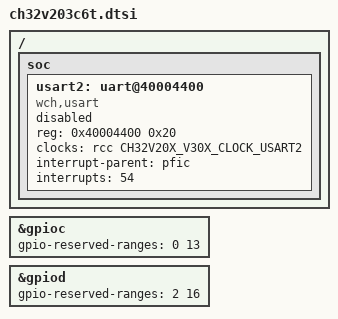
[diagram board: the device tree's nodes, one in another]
/*
 * Copyright (c) 2025 MASSDRIVER EI (massdriver.space)
 *
 * SPDX-License-Identifier: Apache-2.0
 */

#include <wch/ch32v203/ch32v203.dtsi>

/ {
	soc {
		usart2: uart@40004400 {
			compatible = "wch,usart";
			reg = <0x40004400 0x20>;
			clocks = <&rcc CH32V20X_V30X_CLOCK_USART2>;
			interrupt-parent = <&pfic>;
			interrupts = <54>;
			status = "disabled";
		};
	};
};

&gpioc {
	gpio-reserved-ranges = <0 13>;
};

&gpiod {
	gpio-reserved-ranges = <2 16>;
};
